# MAX32550 register map
Vendor: Maxim Integrated; File version: 1.0
Registers are 32-bit, read-write, reset 0x0 unless marked. A register's access mark holds for its fields unless they carry their own. Offsets are from the block's base; [hi:lo] are bit positions; {n}, {i} and the like mark numbered series; 'fields as' and 'values as' point back to an identical list.

## USB — Universal Serial Bus
Base 0x400B0000; register names take the prefix USB_
0x00 CN reset 0xB0 — USB Control Register
  [0] USB_EN — USB Enable
    0=disable; 1=enable
0x200 DEV_ADDR 7-bit — USB Device Address Register
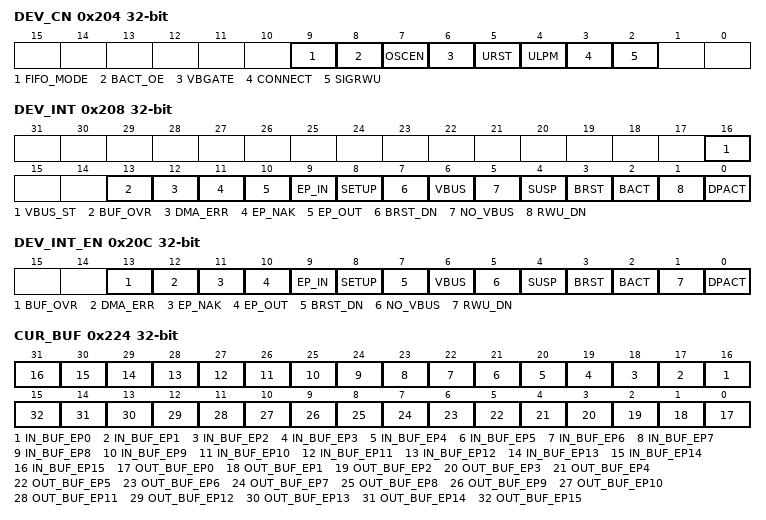
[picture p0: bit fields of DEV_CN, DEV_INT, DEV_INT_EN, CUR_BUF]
0x204 DEV_CN — USB Device Control Register
  [9] FIFO_MODE — FIFO Mode. This setting reduces the likelihood of the device returning NAK due to a busy system bus. In the event of a data underflow (FIFO empty when more data is needed), the device controller will force a bit stuff error on the bus and terminate the packet.
    0=nakUntilComplete (The device controller will return NAK to an IN request until the entire packet has been read from system memory into its internal FIFO.); 1=responOnDataAvail (The device controller will respond to an IN request as soon as data becomes available in the FIFO.)
  [8] BACT_OE — Bus Activity Output Enable
    0=disable; 1=enable
  [7] OSCEN — Oscillator Enable. The oscillator is assumed to be ready when the USB controller is enabled.
    0=disable; 1=enable
  [6] VBGATE — VBUS Gate
    0=alwaysConnect (CONNECT operation independent of VBUS status); 1=connectOnVBUS (CONNECT operation conditional on VBUS present)
  [5] URST — USB Device Controller Reset. When URST is set to 1, the USB controller shall disconnect the device from the USB bus and then reset its states.
    0=notReset; 1=reset
  [4] ULPM — USB Low Power Mode. On receiving a USB suspend interrupt, software can put the USB transceiver into a low power state by setting this bit to 1. To return the USB transceiver to normal operation, software can clear this bit to 0.
    0=disable; 1=enable
  [3] CONNECT — Connect to USB
    0=Disconnect pull up resistor between DPLUS and VBUS; 1=Connect pull up resistor between DPLUS and VBUS
  [2] SIGRWU — USB Signal Remote Wakeup
    0=disable; 1=enable
0x208 DEV_INT (reset mask 0xFFFEFFFF) — USB Device Interrupt Register
  [16] VBUS_ST ro — VBUS Status
    0=lo (Logic 0 (low)); 1=hi (Logic 1 (high))
  [13] BUF_OVR — Buffer Overflow
    0=inactive (No interrupt is pending.); 1=pending (An interrupt is pending.)
  [12] DMA_ERR — DMA Error
    values as BUF_OVR
  [11] EP_NAK — Endpoint NAK Interrupt
    values as BUF_OVR
  [10] EP_OUT — Endpoint OUT Interrupt
    values as BUF_OVR
  [9] EP_IN — Endpoint IN Interrupt
    values as BUF_OVR
  [8] SETUP — Setup Interrupt
    values as BUF_OVR
  [7] BRST_DN — Bus Reset Done
    values as BUF_OVR
  [6] VBUS — VBUS Detect. This bit is cleared by a USB bus reset. This bit can be an interrupt source that will bring the core out of low power mode
    values as BUF_OVR
  [5] NO_VBUS — No VBUS. This bit is cleared by a USB bus reset. This bit can be an interrupt source that will bring the core out of low power mode
    values as BUF_OVR
  [4] SUSP — Suspend. This bit is cleared by a USB bus reset.
    values as BUF_OVR
  [3] BRST — USB Bus Reset. This bit is self-cleared by hardware at the end of the USB reset condition.
    values as BUF_OVR
  [2] BACT — USB Bus Active. This bit is cleared by a USB bus reset.
    values as BUF_OVR
  [1] RWU_DN — Remote Wakeup Signaling Done. This bit is cleared by a USB bus reset.
    values as BUF_OVR
  [0] DPACT — DPLUS Activity. DPLUS activity is an interrupt source that will bring the core out of low power mode.
    values as BUF_OVR
0x20C DEV_INT_EN — USB Device Interrupt Enable Register
  [all] fields
    0=disable; 1=enable
  [13] BUF_OVR — Buffer Overflow
  [12] DMA_ERR — DMA Error Interrupt Enable
  [11] EP_NAK — Endpoint NAK Interrupt Enable
  [10] EP_OUT — Endpoint OUT Interrupt Enable
  [9] EP_IN — Endpoint IN Interrupt Enable
  [8] SETUP — Endpoint SETUP Interrupt Enable
  [7] BRST_DN — Bus Reset Done Interrupt Enable
  [6] VBUS — VBUS Detect Interrupt Enable
  [5] NO_VBUS — No VBUS Interrupt Enable
  [4] SUSP — Suspend Interrupt Enable
  [3] BRST — USB Bus Reset Interrupt Enable
  [2] BACT — USB Bus Active Interrupt Enable
  [1] RWU_DN — Remote Wakeup Signaling Done Interrupt Enable
  [0] DPACT — DPLUS Activity Interrupt Enable
0x220 EP_BASE — USB Endpoint Descriptor Base Address Register
  [31:9] EP_BASE — USB_Endpoint Descriptor Base Address. This register defines the starting address of the endpoint descriptor in system memory. The descriptor address of each buffer in the endpoint is formed by: EP_BASE[31:9] : EP_DESCRIPTOR_OFFSET.
0x224 CUR_BUF — USB Current Buffer Register
  [n+16] IN_BUF_EP{n} (n=0..15) — EP{n} IN Transfer Current Buffer
  [n] OUT_BUF_EP{n} (n=0..15) — EP{n} OUT Transfer Current Buffer
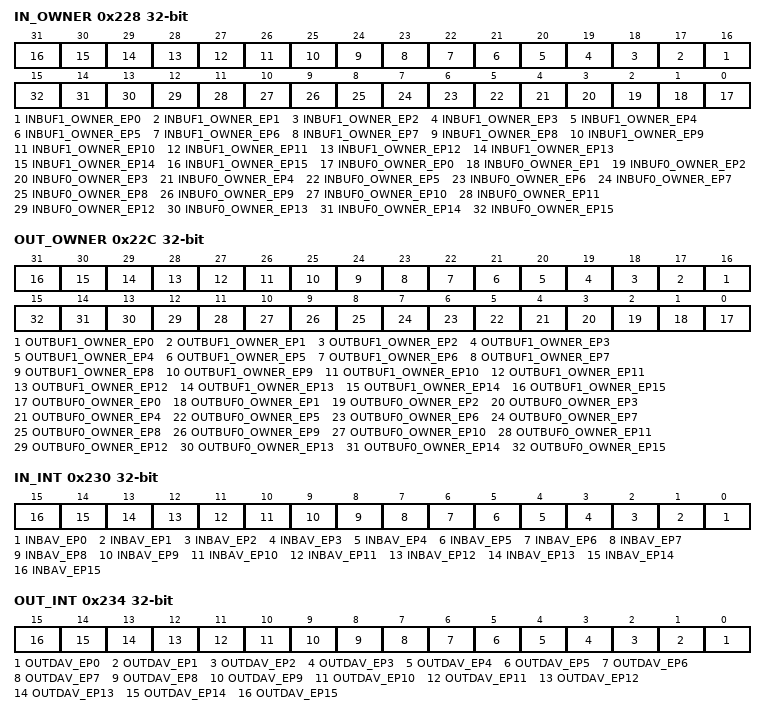
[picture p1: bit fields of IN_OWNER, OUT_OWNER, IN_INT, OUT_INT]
0x228 IN_OWNER — USB IN Buffer Owner Register
  [n+16] INBUF1_OWNER_EP{n} (n=0..15) — EP{n} IN Buffer 1 Owner
    0=software (This endpoint's IN buffer 1 is owned by the software.); 1=usbController (This endpoint's IN buffer 1 is owned by the USB controller.)
  [n] INBUF0_OWNER_EP{n} (n=0..15) — EP{n} IN Buffer 0 Owner
    0=software (This endpoint's IN buffer 0 is owned by the software.); 1=usbController (This endpoint's IN buffer 0 is owned by the USB controller.)
0x22C OUT_OWNER — USB OUT Buffer Owner Register
  [n+16] OUTBUF1_OWNER_EP{n} (n=0..15) — EP{n} OUT Buffer 1 Owner
    0=software (This endpoint's OUT buffer 1 is owned by the software.); 1=usbController (This endpoint's OUT buffer 1 is owned by the USB controller.)
  [n] OUTBUF0_OWNER_EP{n} (n=0..15) — EP{n} OUT Buffer 0 Owner
    0=software (This endpoint's OUT buffer 0 is owned by the software.); 1=usbController (This endpoint's OUT buffer 0 is owned by the USB controller.)
0x230 IN_INT — USB IN Interrupt Register
  [all] fields
    values as DEV_INT.BUF_OVR
  [n] INBAV_EP{n} (n=0..15) — EP{n} IN Buffer Available Interrupt
0x234 OUT_INT — USB OUT Interrupt Register
  [all] fields
    values as DEV_INT.BUF_OVR
  [n] OUTDAV_EP{n} (n=0..15) — EP{n} OUT Buffer Data Available Interrupt
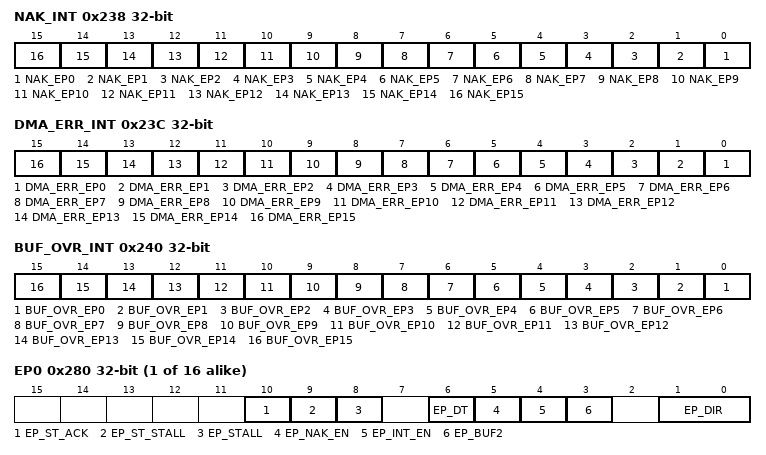
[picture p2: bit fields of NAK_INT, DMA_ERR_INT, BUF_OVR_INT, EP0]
0x238 NAK_INT — USB NAK Interrupt Register
  [all] fields
    values as DEV_INT.BUF_OVR
  [n] NAK_EP{n} (n=0..15) — EP{n} NAK Interrupt
0x23C DMA_ERR_INT — USB DMA Error Interrupt Register
  [all] fields
    values as DEV_INT.BUF_OVR
  [n] DMA_ERR_EP{n} (n=0..15) — EP{n} DMA Error Interrupt
0x240 BUF_OVR_INT — USB Buffer Overflow Interrupt Register
  [all] fields
    values as DEV_INT.BUF_OVR
  [n] BUF_OVR_EP{n} (n=0..15) — EP{n} Buffer Overflow Interrupt
{0x260+4i} SETUP{i} (i=0..1) ro — USB SETUP Register
{0x280+4i} EP{i} (i=0..15) — USB Endpoint Control Register
  [10] EP_ST_ACK — Acknowledge Status Stage of Control Transfer. This bit determines whether an ACK will be returned to the Status Stage of a control transfer. Until software either acknowledges (EP_ST_ACK=1) or stalls the transfer (EP_ST_STALL=1), the SIE answers the status stage of a CONTROL transfer with the NAK handshake. Regardless of the setting of this bit, a CONTROL endpoint must receive a SETUP packet and respond with ACK if the packet is received successfully. Upon receiving a SETUP packet, this bit is automatically cleared to 0.
    0=disable; 1=enable
  [9] EP_ST_STALL — Stall Status Stage of Control Transfer. This bit determines whether a STALL will be returned to the Status Stage of a control transfer. The Stall Status Stage bit, together with the EP_ST_ACK bit, indicates to the SIE how to respond in the status stage of a Control transfer. The EP_ST_STALL has priority over EP_ST_ACK. Until software either acknowledges (EP_ST_ACK=1) or stalls the transfer (EP_ST_STALL=1), the SIE answers the status stage of a CONTROL transfer with the NAK handshake. Regardless of the setting of this bit, a CONTROL endpoint must receive a SETUP packet and respond with ACK if the packet is received successfully. Upon receiving a SETUP packet, this bit is automatically cleared to 0.
    0=disable; 1=enable
  [8] EP_STALL — Endpoint Stalled. Any access to a stalled endpoint will cause the USB interface to return a STALL handshake. For CONTROL endpoint, this bit is automatically cleared to 0 upon receiving a SETUP packet.
    0=notStalled; 1=stalled
  [6] EP_DT — Endpoint Data Toggle Clear
    0=complete (No operation/complete); 1=Start operation
  [5] EP_NAK_EN — Endpoint NAK Interrupt Enable
    0=disable; 1=enable
  [4] EP_INT_EN — Endpoint Interrupt Enable
    0=disable; 1=enable
  [3] EP_BUF2 — Double Buffer Enable. For a single buffered endpoint, the SIE will only use buffer 0 associated with the endpoint transfer direction. For a doubled buffered endpoint, the SIE will ping pong between the two buffers. This allows the SIE to transfer data to/from system memory while still communicating data to/from the host.
    0=disable; 1=enable
  [1:0] EP_DIR — Endpoint Direction
    0=disable; 1=out; 2=in; 3=control (This configures the endpoint to be a CONTROL pipe accepting IN, OUT and SETUP packets.)
